# STM32WL3xx register map
File version: 1.0
Registers are 32-bit, read-write, reset 0x0 unless marked. A register's access mark holds for its fields unless they carry their own. Offsets are from the block's base; [hi:lo] are bit positions; {n}, {i} and the like mark numbered series.

## DAC1 — Digital to Analog Converter (DAC)
Base 0x40006000
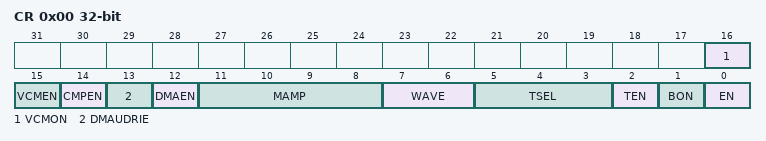
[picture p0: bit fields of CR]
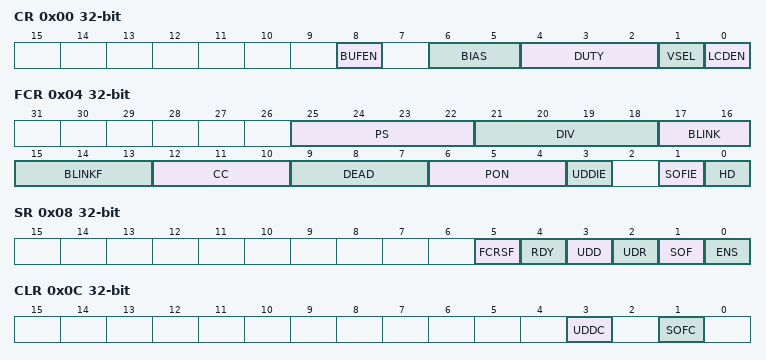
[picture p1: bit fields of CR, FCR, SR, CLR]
0x00 CR — (@ 0x00000000) Control register
  [16] VCMON, [15] VCMEN, [14] CMPEN, [13] DMAUDRIE, [12] DMAEN, [11:8] MAMP, [7:6] WAVE, [5:3] TSEL, [2] TEN, [1] BON, [0] EN
0x04 SWTRIGR — (@ 0x00000004) Software trigger register
  [0] SWTRIG
0x10 DHR — (@ 0x00000010) Channel data holding register
  [5:0] DACDHR
0x2C DOR — (@ 0x0000002C) Channel data output register
  [5:0] DACDOR
0x34 SR — (@ 0x00000034) Status register
  [13] DMAUDR

## LCD — Liquid crystal display controller (LCD)
Base 0x40007000
0x00 CR — (@ 0x00000000) Control register
  [8] BUFEN, [6:5] BIAS, [4:2] DUTY, [1] VSEL, [0] LCDEN
0x04 FCR — (@ 0x00000004) Frame control register
  [25:22] PS, [21:18] DIV, [17:16] BLINK, [15:13] BLINKF, [12:10] CC, [9:7] DEAD, [6:4] PON, [3] UDDIE, [1] SOFIE, [0] HD
0x08 SR — (@ 0x00000008) Status register
  [5] FCRSF, [4] RDY, [3] UDD, [2] UDR, [1] SOF, [0] ENS
0x0C CLR — (@ 0x0000000C) Clear register
  [3] UDDC, [1] SOFC
{0x14+8i} RAM_COM{i} (i=0..7) — (@ {0x14+8i}) Disaplay Memory COM {i}
  [15:0] SEGMENT_DATA

## DBGMCU — MCU debug component (DBGMCU)
Base 0x40008000
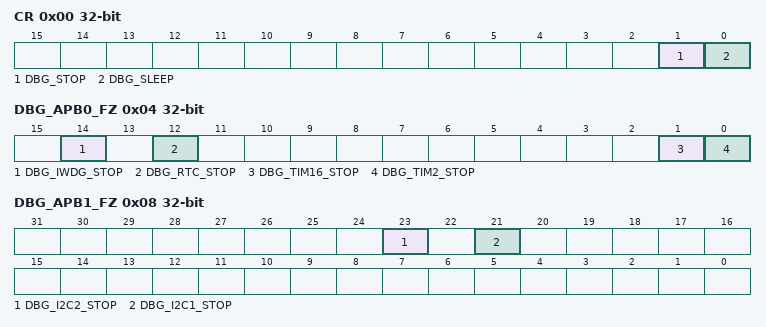
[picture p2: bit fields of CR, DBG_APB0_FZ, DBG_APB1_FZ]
0x00 CR — (@ 0x00000000) CR register
  [1] DBG_STOP, [0] DBG_SLEEP
0x04 DBG_APB0_FZ — (@ 0x00000004) DBG_APB0_FZ register
  [14] DBG_IWDG_STOP, [12] DBG_RTC_STOP, [1] DBG_TIM16_STOP, [0] DBG_TIM2_STOP
0x08 DBG_APB1_FZ — (@ 0x00000008) DBG_APB1_FZ register
  [23] DBG_I2C2_STOP, [21] DBG_I2C1_STOP

## COMP1 — Comparator (COMP)
Base 0x40009000
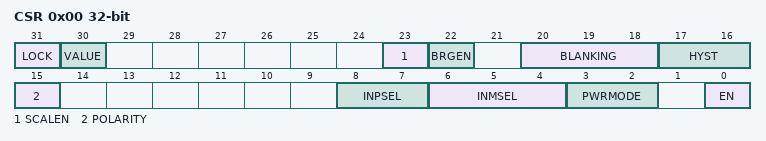
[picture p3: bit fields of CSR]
0x00 CSR — (@ 0x00000000) Control and status register
  [31] LOCK
  [30] VALUE
  [23] SCALEN
  [22] BRGEN
  [20:18] BLANKING
  [17:16] HYST
    0=NONE (No hysteresis); 1=LOW (Hysteresis level low); 2=MEDIUM (Hysteresis level medium); 3=HIGH (Hysteresis level high)
  [15] POLARITY
    0=NONINVERTED (COMP output polarity is not inverted: comparator output is high when the plus (non-inverting) input is at a higher voltage than the minus (inverting) input); 1=INVERTED (COMP output polarity is inverted: comparator output is low when the plus (non-inverting) input is at a lower voltage than the minus (inverting) input)
  [8:7] INPSEL
    0=IO1 (Comparator input plus connected to IO1 (pin PA14 for COMP1).); 1=IO2 (Comparator input plus connected to IO2 (pin PB1 for COMP1)); 2=IO3 (Comparator input plus connected to IO3 (pin PB2 for COMP1))
  [6:4] INMSEL
  [3:2] PWRMODE
    0=HIGHSPEED (COMP power mode to high speed); 1=MEDIUMSPEED (COMP power mode to medium speed); 3=ULTRALOWPOWER (COMP power mode to ultra-low power)
  [0] EN

## LCSC — LC Sensor Controller (LCSC)
Base 0x4000A000
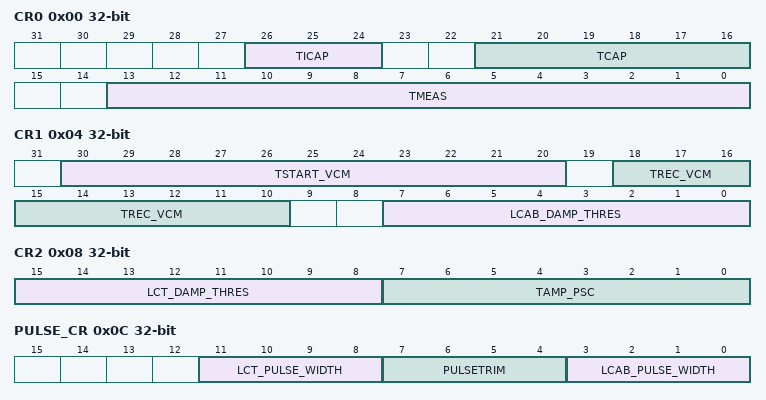
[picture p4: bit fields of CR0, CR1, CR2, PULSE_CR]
0x00 CR0 — (@ 0x00000000) LCSC_CR0 register
  [26:24] TICAP, [21:16] TCAP, [13:0] TMEAS
0x04 CR1 — (@ 0x00000004) LCSC_CR1 register
  [30:20] TSTART_VCM, [18:10] TREC_VCM, [7:0] LCAB_DAMP_THRES
0x08 CR2 — (@ 0x00000008) LCSC_CR2 register
  [15:8] LCT_DAMP_THRES, [7:0] TAMP_PSC
0x0C PULSE_CR — (@ 0x0000000C) LCSC_PULSE_CR register
  [11:8] LCT_PULSE_WIDTH, [7:4] PULSETRIM, [3:0] LCAB_PULSE_WIDTH
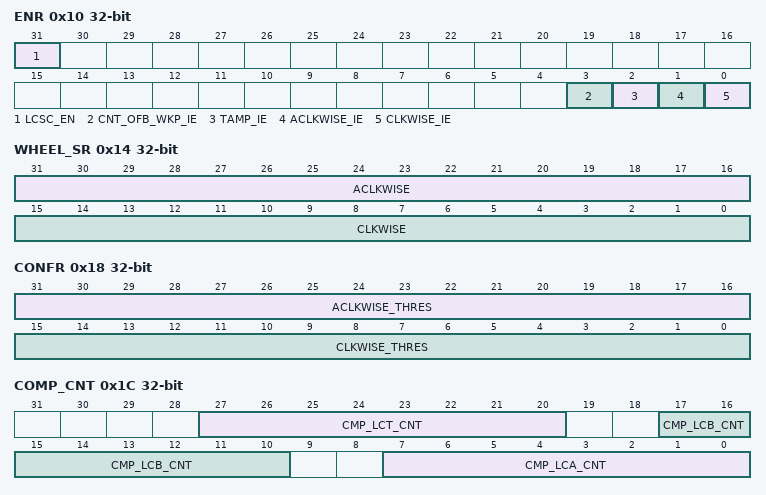
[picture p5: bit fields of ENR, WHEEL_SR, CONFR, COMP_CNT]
0x10 ENR — (@ 0x00000010) LCSC_ENR register
  [31] LCSC_EN, [3] CNT_OFB_WKP_IE, [2] TAMP_IE, [1] ACLKWISE_IE, [0] CLKWISE_IE
0x14 WHEEL_SR — (@ 0x00000014) LCSC_WHEEL_SR register
  [31:16] ACLKWISE, [15:0] CLKWISE
0x18 CONFR — (@ 0x00000018) LCSC_CONFR register
  [31:16] ACLKWISE_THRES, [15:0] CLKWISE_THRES
0x1C COMP_CNT — (@ 0x0000001C) LCSC_COMP_CNT register
  [27:20] CMP_LCT_CNT, [17:10] CMP_LCB_CNT, [7:0] CMP_LCA_CNT
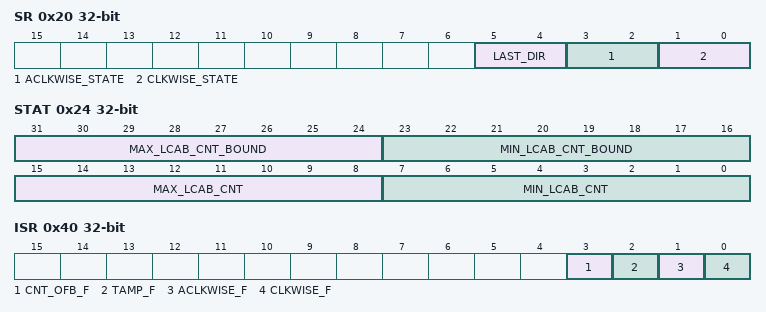
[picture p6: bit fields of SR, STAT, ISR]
0x20 SR — (@ 0x00000020) LCSC_SR register
  [5:4] LAST_DIR, [3:2] ACLKWISE_STATE, [1:0] CLKWISE_STATE
0x24 STAT — (@ 0x00000024) LCSC_STAT register
  [31:24] MAX_LCAB_CNT_BOUND, [23:16] MIN_LCAB_CNT_BOUND, [15:8] MAX_LCAB_CNT, [7:0] MIN_LCAB_CNT
0x40 ISR — (@ 0x00000044) LCSC_ISR register
  [3] CNT_OFB_F, [2] TAMP_F, [1] ACLKWISE_F, [0] CLKWISE_F
